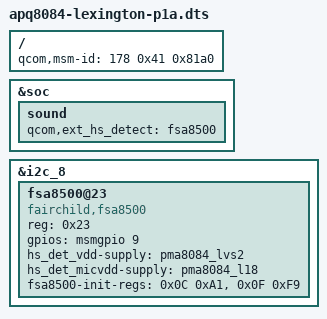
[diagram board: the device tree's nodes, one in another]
/* Copyright (c) 2013, The Linux Foundation. All rights reserved.
 * Copyright (c) 2014 Motorola Mobility LLC
 *
 * This program is free software; you can redistribute it and/or modify
 * it under the terms of the GNU General Public License version 2 and
 * only version 2 as published by the Free Software Foundation.
 *
 * This program is distributed in the hope that it will be useful,
 * but WITHOUT ANY WARRANTY; without even the implied warranty of
 * MERCHANTABILITY or FITNESS FOR A PARTICULAR PURPOSE.  See the
 * GNU General Public License for more details.
 */

/dts-v1/;

#include "apq8084.dtsi"
#include "apq8084-lexington.dtsi"
#include "apq8084-moto-old-pwr-grid.dtsi"

/ {
	qcom,msm-id = <178 0x41 0x81a0>;
	/delete-node/ cycapsense_prog;
};
&soc {
	sound {
		qcom,ext_hs_detect = "fsa8500";
	};
};
&i2c_8 {
	/delete-node/ tpa6165xx@40;

	fsa8500@23 {
		compatible = "fairchild,fsa8500";
		reg = <0x23>;
		gpios = <&msmgpio 9 0x0>;
		hs_det_vdd-supply = <&pma8084_lvs2>;
		hs_det_micvdd-supply = <&pma8084_l18>;
		fsa8500-init-regs = <0x0C 0xA1>,
				    <0x0F 0xF9>;
	};
};
